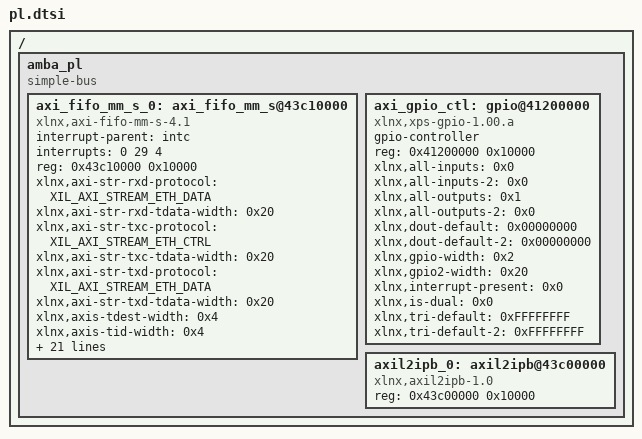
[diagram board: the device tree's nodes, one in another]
/*
 * CAUTION: This file is automatically generated by Xilinx.
 * Version:  
 * Today is: Wed Jan 31 22:07:57 2018
 */


/ {
	amba_pl: amba_pl {
		#address-cells = <1>;
		#size-cells = <1>;
		compatible = "simple-bus";
		ranges ;
		axi_fifo_mm_s_0: axi_fifo_mm_s@43c10000 {
			compatible = "xlnx,axi-fifo-mm-s-4.1";
			interrupt-parent = <&intc>;
			interrupts = <0 29 4>;
			reg = <0x43c10000 0x10000>;
			xlnx,axi-str-rxd-protocol = "XIL_AXI_STREAM_ETH_DATA";
			xlnx,axi-str-rxd-tdata-width = <0x20>;
			xlnx,axi-str-txc-protocol = "XIL_AXI_STREAM_ETH_CTRL";
			xlnx,axi-str-txc-tdata-width = <0x20>;
			xlnx,axi-str-txd-protocol = "XIL_AXI_STREAM_ETH_DATA";
			xlnx,axi-str-txd-tdata-width = <0x20>;
			xlnx,axis-tdest-width = <0x4>;
			xlnx,axis-tid-width = <0x4>;
			xlnx,axis-tuser-width = <0x4>;
			xlnx,data-interface-type = <0x0>;
			xlnx,has-axis-tdest = <0x0>;
			xlnx,has-axis-tid = <0x0>;
			xlnx,has-axis-tkeep = <0x1>;
			xlnx,has-axis-tstrb = <0x1>;
			xlnx,has-axis-tuser = <0x0>;
			xlnx,rx-fifo-depth = <0x200>;
			xlnx,rx-fifo-pe-threshold = <0x2>;
			xlnx,rx-fifo-pf-threshold = <0x1fb>;
			xlnx,s-axi-id-width = <0x4>;
			xlnx,s-axi4-data-width = <0x20>;
			xlnx,select-xpm = <0x0>;
			xlnx,tx-fifo-depth = <0x200>;
			xlnx,tx-fifo-pe-threshold = <0x2>;
			xlnx,tx-fifo-pf-threshold = <0x1fb>;
			xlnx,use-rx-cut-through = <0x0>;
			xlnx,use-rx-data = <0x1>;
			xlnx,use-tx-ctrl = <0x0>;
			xlnx,use-tx-cut-through = <0x0>;
			xlnx,use-tx-data = <0x1>;
		};
		axi_gpio_ctl: gpio@41200000 {
			#gpio-cells = <2>;
			compatible = "xlnx,xps-gpio-1.00.a";
			gpio-controller ;
			reg = <0x41200000 0x10000>;
			xlnx,all-inputs = <0x0>;
			xlnx,all-inputs-2 = <0x0>;
			xlnx,all-outputs = <0x1>;
			xlnx,all-outputs-2 = <0x0>;
			xlnx,dout-default = <0x00000000>;
			xlnx,dout-default-2 = <0x00000000>;
			xlnx,gpio-width = <0x2>;
			xlnx,gpio2-width = <0x20>;
			xlnx,interrupt-present = <0x0>;
			xlnx,is-dual = <0x0>;
			xlnx,tri-default = <0xFFFFFFFF>;
			xlnx,tri-default-2 = <0xFFFFFFFF>;
		};
		axil2ipb_0: axil2ipb@43c00000 {
			compatible = "xlnx,axil2ipb-1.0";
			reg = <0x43c00000 0x10000>;
		};
	};
};
